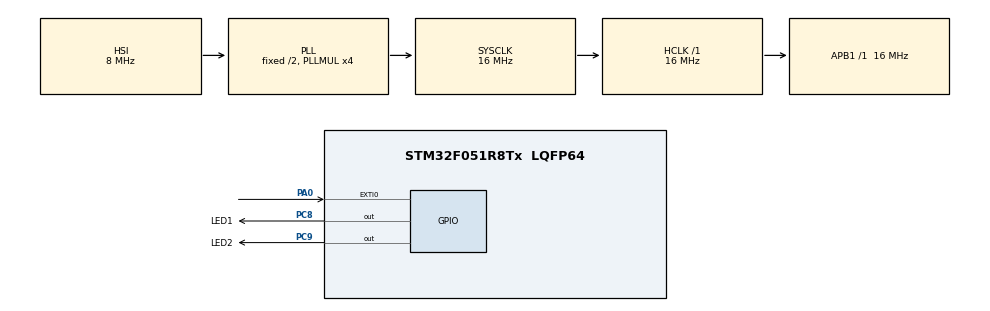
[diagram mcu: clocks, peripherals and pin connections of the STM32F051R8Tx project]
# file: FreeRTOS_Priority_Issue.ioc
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FREERTOS.Events01=myEvent01,Dynamic,NULL
FREERTOS.INCLUDE_uxTaskPriorityGet=1
FREERTOS.INCLUDE_vTaskSuspend=0
FREERTOS.Mutexes01=Mutex_1,Dynamic,NULL
FREERTOS.Tasks01=TaskH,47,128,TaskH_Func,Default,NULL,Dynamic,NULL,NULL;TaskL,8,128,TaskL_Func,Default,NULL,Dynamic,NULL,NULL;TaskM,15,128,TaskM_Func,Default,NULL,Dynamic,NULL,NULL
FREERTOS.configTOTAL_HEAP_SIZE=3072
FREERTOS.configUSE_NEWLIB_REENTRANT=0
FREERTOS.configUSE_TRACE_FACILITY=0
Mcu.Family=STM32F0
Mcu.Name=STM32F051R8Tx
Mcu.Package=LQFP64
NVIC.EXTI0_1_IRQn=true\:3\:0\:false\:false\:true\:true\:true\:true\:true
NVIC.TIM6_DAC_IRQn=true\:3\:0\:false\:false\:true\:false\:false\:true\:true
NVIC.TimeBase=TIM6_DAC_IRQn
NVIC.TimeBaseIP=TIM6
PA0.Signal=GPXTI0
PC8.GPIO_Label=LED1
PC8.Signal=GPIO_Output
PC9.GPIO_Label=LED2
PC9.Signal=GPIO_Output
PF0-OSC_IN.Mode=HSE-External-Clock-Source
PF0-OSC_IN.Signal=RCC_OSC_IN
ProjectManager.HeapSize=0x200
ProjectManager.StackSize=0x400
ProjectManager.TargetToolchain=STM32CubeIDE
RCC.AHBFreq_Value=16000000
RCC.APB1Freq_Value=16000000
RCC.APB1TimFreq_Value=16000000
RCC.HCLKFreq_Value=16000000
RCC.PLLMUL=RCC_PLL_MUL4
RCC.SYSCLKFreq_VALUE=16000000
RCC.SYSCLKSource=RCC_SYSCLKSOURCE_PLLCLK
VP_FREERTOS_VS_CMSIS_V2.Mode=CMSIS_V2
VP_SYS_VS_tim6.Mode=TIM6
board=custom

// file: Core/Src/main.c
/* USER CODE BEGIN Header */
/**
  ******************************************************************************
  * @file           : main.c
  * @brief          : Main program body
  ******************************************************************************
  * @attention
  *
  * Copyright (c) 2026 STMicroelectronics.
  * All rights reserved.
  *
  * This software is licensed under terms that can be found in the LICENSE file
  * in the root directory of this software component.
  * If no LICENSE file comes with this software, it is provided AS-IS.
  *
  ******************************************************************************
  */
/* USER CODE END Header */
#include "main.h"
#include "cmsis_os.h"

/* Definitions for TaskH */
osThreadId_t TaskHHandle;
const osThreadAttr_t TaskH_attributes = {
  .name = "TaskH",
  .stack_size = 128 * 4,
  .priority = (osPriority_t) osPriorityHigh7,
};
/* Definitions for TaskL */
osThreadId_t TaskLHandle;
const osThreadAttr_t TaskL_attributes = {
  .name = "TaskL",
  .stack_size = 128 * 4,
  .priority = (osPriority_t) osPriorityLow,
};
/* Definitions for TaskM */
osThreadId_t TaskMHandle;
const osThreadAttr_t TaskM_attributes = {
  .name = "TaskM",
  .stack_size = 128 * 4,
  .priority = (osPriority_t) osPriorityLow7,
};
/* Definitions for Mutex_1 */
osMutexId_t Mutex_1Handle;
const osMutexAttr_t Mutex_1_attributes = {
  .name = "Mutex_1"
};
/* Definitions for myEvent01 */
osEventFlagsId_t myEvent01Handle;
const osEventFlagsAttr_t myEvent01_attributes = {
  .name = "myEvent01"
};
/* USER CODE BEGIN PV */

osSemaphoreId_t semaphore1;
uint8_t trigger = 0;
const osSemaphoreAttr_t sm_attr = {
		.name = "mySemaphore1"
};
/* USER CODE END PV */

void SystemClock_Config(void);
static void MX_GPIO_Init(void);
void TaskH_Func(void *argument);
void TaskL_Func(void *argument);
void TaskM_Func(void *argument);

/* USER CODE BEGIN 0 */
void HAL_GPIO_EXTI_Callback(uint16_t GPIO_Pin)
{
	if(GPIO_Pin == GPIO_PIN_0)
	{
		trigger = 1;
		//osSemaphoreRelease(Mutex_1Handle);
		portYIELD_FROM_ISR(pdTRUE);
	}
}
/* USER CODE END 0 */

int main(void)
{

  /* MCU Configuration--------------------------------------------------------*/

  /* Reset of all peripherals, Initializes the Flash interface and the Systick. */
  HAL_Init();

  /* Configure the system clock */
  SystemClock_Config();

  /* Initialize all configured peripherals */
  MX_GPIO_Init();

  /* Init scheduler */
  osKernelInitialize();
  /* Create the mutex(es) */
  /* creation of Mutex_1 */
  Mutex_1Handle = osMutexNew(&Mutex_1_attributes);

  /* USER CODE BEGIN RTOS_MUTEX */
  semaphore1 = osSemaphoreNew(1, 1, &sm_attr);
  osThreadId_t getID = osMutexGetOwner(Mutex_1Handle);
  /* USER CODE END RTOS_MUTEX */

  /* Create the thread(s) */
  /* creation of TaskH */
  TaskHHandle = osThreadNew(TaskH_Func, NULL, &TaskH_attributes);

  /* creation of TaskL */
  TaskLHandle = osThreadNew(TaskL_Func, NULL, &TaskL_attributes);

  /* creation of TaskM */
  TaskMHandle = osThreadNew(TaskM_Func, NULL, &TaskM_attributes);

  /* USER CODE BEGIN RTOS_THREADS */
  /* add threads, ... */
  osPriority_t pTaskH = osThreadGetPriority(TaskHHandle);
  osPriority_t pTaskL = osThreadGetPriority(TaskLHandle);
  osPriority_t pTaskM = osThreadGetPriority(TaskMHandle);
  /* USER CODE END RTOS_THREADS */

  /* creation of myEvent01 */
  myEvent01Handle = osEventFlagsNew(&myEvent01_attributes);

  /* Start scheduler */
  osKernelStart();

  /* We should never get here as control is now taken by the scheduler */
  /* Infinite loop */
  while (1)
  {

  }
}

void SystemClock_Config(void)
{
  RCC_OscInitTypeDef RCC_OscInitStruct = {0};
  RCC_ClkInitTypeDef RCC_ClkInitStruct = {0};

  /** Initializes the RCC Oscillators according to the specified parameters
  * in the RCC_OscInitTypeDef structure.
  */
  RCC_OscInitStruct.OscillatorType = RCC_OSCILLATORTYPE_HSI;
  RCC_OscInitStruct.HSIState = RCC_HSI_ON;
  RCC_OscInitStruct.HSICalibrationValue = RCC_HSICALIBRATION_DEFAULT;
  RCC_OscInitStruct.PLL.PLLState = RCC_PLL_ON;
  RCC_OscInitStruct.PLL.PLLSource = RCC_PLLSOURCE_HSI;
  RCC_OscInitStruct.PLL.PLLMUL = RCC_PLL_MUL4;
  RCC_OscInitStruct.PLL.PREDIV = RCC_PREDIV_DIV1;
  if (HAL_RCC_OscConfig(&RCC_OscInitStruct) != HAL_OK)
  {
    Error_Handler();
  }

  /** Initializes the CPU, AHB and APB buses clocks
  */
  RCC_ClkInitStruct.ClockType = RCC_CLOCKTYPE_HCLK|RCC_CLOCKTYPE_SYSCLK
                              |RCC_CLOCKTYPE_PCLK1;
  RCC_ClkInitStruct.SYSCLKSource = RCC_SYSCLKSOURCE_PLLCLK;
  RCC_ClkInitStruct.AHBCLKDivider = RCC_SYSCLK_DIV1;
  RCC_ClkInitStruct.APB1CLKDivider = RCC_HCLK_DIV1;

  if (HAL_RCC_ClockConfig(&RCC_ClkInitStruct, FLASH_LATENCY_0) != HAL_OK)
  {
    Error_Handler();
  }
}

static void MX_GPIO_Init(void)
{
  GPIO_InitTypeDef GPIO_InitStruct = {0};

  /* GPIO Ports Clock Enable */
  __HAL_RCC_GPIOF_CLK_ENABLE();
  __HAL_RCC_GPIOA_CLK_ENABLE();
  __HAL_RCC_GPIOC_CLK_ENABLE();

  /*Configure GPIO pin Output Level */
  HAL_GPIO_WritePin(GPIOC, LED1_Pin|LED2_Pin, GPIO_PIN_RESET);

  /*Configure GPIO pin : PA0 */
  GPIO_InitStruct.Pin = GPIO_PIN_0;
  GPIO_InitStruct.Mode = GPIO_MODE_IT_RISING;
  GPIO_InitStruct.Pull = GPIO_NOPULL;
  HAL_GPIO_Init(GPIOA, &GPIO_InitStruct);

  /*Configure GPIO pins : LED1_Pin LED2_Pin */
  GPIO_InitStruct.Pin = LED1_Pin|LED2_Pin;
  GPIO_InitStruct.Mode = GPIO_MODE_OUTPUT_PP;
  GPIO_InitStruct.Pull = GPIO_NOPULL;
  GPIO_InitStruct.Speed = GPIO_SPEED_FREQ_LOW;
  HAL_GPIO_Init(GPIOC, &GPIO_InitStruct);

  /* EXTI interrupt init*/
  HAL_NVIC_SetPriority(EXTI0_1_IRQn, 3, 0);
  HAL_NVIC_EnableIRQ(EXTI0_1_IRQn);

}

void TaskH_Func(void *argument)
{
  /* USER CODE BEGIN 5 */
  /* Infinite loop */
	osDelay(200);
  for(;;)
  {
	  osStatus_t stat = osMutexAcquire(Mutex_1Handle, portMAX_DELAY);
	  ////osStatus_t stat = osSemaphoreAcquire(semaphore1, portMAX_DELAY);
	  if(stat == osOK)
	  {
		  HAL_GPIO_TogglePin(GPIOC, LED2_Pin);
		  for(volatile uint32_t i = 0; i < 500000; i++);
		  osMutexRelease(Mutex_1Handle);
		  ////osSemaphoreRelease(semaphore1);
	  }
	  osDelay(100);
  }
  /* USER CODE END 5 */
}

void TaskL_Func(void *argument)
{
  /* USER CODE BEGIN TaskL_Func */
  /* Infinite loop */
	int i = 0;
  for(;;)
  {
	  osStatus_t stat = osMutexAcquire(Mutex_1Handle, portMAX_DELAY);
	  ////osStatus_t stat = osSemaphoreAcquire(semaphore1, portMAX_DELAY);
	  if(stat == osOK)
	  {
		  for(volatile uint32_t i = 0; i < 1500000; i++);
		  if(trigger == 1)
		  {
			  trigger = 0;
			  for(i = 0; i < 500000; i++)
			  {
				  osPriority_t pTaskH = osThreadGetPriority(TaskHHandle);
				  osPriority_t pTaskL = osThreadGetPriority(TaskLHandle);
				  osPriority_t pTaskM = osThreadGetPriority(TaskMHandle);
			  }
		  }
		  osMutexRelease(Mutex_1Handle);
		  ////osSemaphoreRelease(semaphore1);
		  osDelay(100);
	  }

  }
  /* USER CODE END TaskL_Func */
}

void TaskM_Func(void *argument)
{
  /* USER CODE BEGIN TaskM_Func */
  /* Infinite loop */
	osDelay(5000);
  for(;;)
  {
	  for(volatile uint32_t i = 0; i < 50000; i++);
  }
  /* USER CODE END TaskM_Func */
}

void HAL_TIM_PeriodElapsedCallback(TIM_HandleTypeDef *htim)
{
  if (htim->Instance == TIM6) {
    HAL_IncTick();
  }
}

void Error_Handler(void)
{
  __disable_irq();
  while (1)
  {
  }
}
